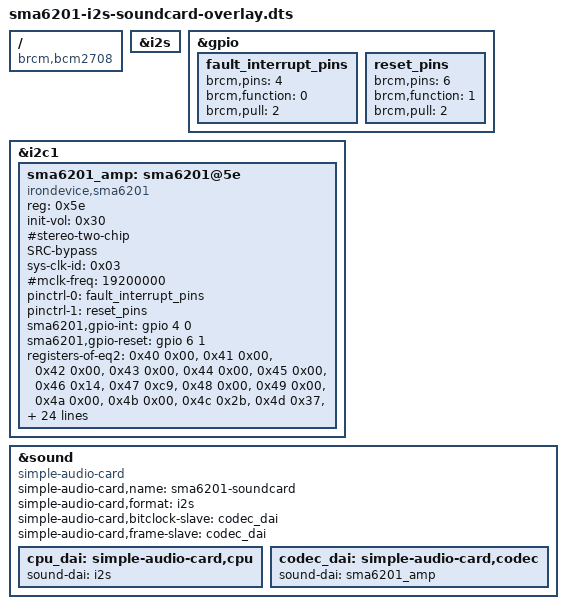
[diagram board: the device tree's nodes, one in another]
/*
 * Definitions for SMA6201 Amp
 * name : sma6201-i2s-soundcard-overlay.dts
 * Compile for dts
 * dtc -@ -I dts -O dtb -o sma6201-i2s-soundcard.dtbo
 *			sma6201-i2s-soundcard-overlay.dts
 * sudo cp sma6201-i2s-soundcard.dtbo /boot/overlays
 * adding dtoverlay sma6201-i2s-soundcard.dtbo in config.txt
 */

/dts-v1/;
/plugin/;

/ {
	compatible = "brcm,bcm2708";

	fragment@0 {
		target = <&i2s>;
		__overlay__ {
			status = "okay";
		};
	};

	fragment@1 {
		target = <&gpio>;
		__overlay__ {
			fault_interrupt_pins: fault_interrupt_pins {
				brcm,pins = <4>;
				brcm,function = <0>; /* input */
				brcm,pull = <2>; /* pull-up */
			};
			reset_pins: reset_pins {
				brcm,pins = <6>;
				brcm,function = <1>; /* Output */
				brcm,pull = <2>; /* pull-up */
			};
		};
	};

	fragment@2 {
		target = <&i2c1>;
		__overlay__ {
			#address-cells = <1>;
			#size-cells = <0>;
			status = "okay";

			sma6201_amp: sma6201@5e {
				#sound-dai-cells = <0>;
				compatible = "irondevice,sma6201";
				reg = <0x5e>;
				init-vol = <0x30>;
				#stereo-two-chip;
				SRC-bypass;
				/* SMA6201_EXTERNAL_CLOCK_19_2   : 0x00,
				 * SMA6201_EXTERNAL_CLOCK_24_576 : 0x01,
				 * SMA6201_PLL_CLKIN_MCLK        : 0x02,
				 * SMA6201_PLL_CLKIN_BCLK        : 0x03
				 */
				sys-clk-id = <0x03>;
				/* Valid when sys-clk-id 0x02 */
				#mclk-freq = <19200000>;
				pinctrl-names = "default";
				pinctrl-0 = <&fault_interrupt_pins>;
				pinctrl-1 = <&reset_pins>;
				sma6201,gpio-int= <&gpio 4 0>;
				sma6201,gpio-reset= <&gpio 6 1>;

				status = "okay";
				registers-of-eq2 = <0x40 0x00>,<0x41 0x00>,
						   <0x42 0x00>,<0x43 0x00>,
						   <0x44 0x00>,<0x45 0x00>,
						   <0x46 0x14>,<0x47 0xc9>,
						   <0x48 0x00>,<0x49 0x00>,
						   <0x4a 0x00>,<0x4b 0x00>,
						   <0x4c 0x2b>,<0x4d 0x37>,
						   <0x4e 0x00>,<0x4f 0x2a>,
						   <0x50 0x69>,<0x51 0x04>,
						   <0x52 0x99>,<0x53 0xf8>,
						   <0x54 0x02>,<0x55 0x40>,
						   <0x56 0x00>,<0x57 0x00>,
						   <0x58 0xd5>,<0x59 0x96>,
						   <0x5a 0x04>,<0x5b 0x66>,
						   <0x5c 0x07>,<0x5d 0x06>,
						   <0x5e 0x11>,<0x5f 0xb3>,
						   <0x60 0x04>,<0x61 0xce>,
						   <0x62 0x43>,<0x63 0x03>,
						   <0x64 0x40>,<0x65 0x00>,
						   <0x66 0x00>,<0x67 0xee>,
						   <0x68 0x4c>,<0x69 0x04>,
						   <0x6a 0x31>,<0x6b 0xbc>,
						   <0x6c 0x05>,<0x6d 0x0a>,
						   <0x6e 0xaa>,<0x6f 0x05>,
						   <0x70 0x00>,<0x71 0x00>,
						   <0x72 0x00>,<0x73 0x40>,
						   <0x74 0x00>,<0x75 0x00>,
						   <0x76 0xf5>,<0x77 0x55>,
						   <0x78 0x03>,<0x79 0x00>,
						   <0x7a 0x00>,<0x7b 0x00>,
						   <0x7c 0x3d>,<0x7d 0xa6>,
						   <0x7e 0x04>,<0x7f 0x82>,
						   <0x80 0x64>,<0x81 0x04>,
						   <0x82 0x40>,<0x83 0x00>,
						   <0x84 0x00>,<0x85 0xc2>,
						   <0x86 0x59>,<0x87 0x04>,
						   <0x88 0x7d>,<0x89 0x9b>,
						   <0x8a 0x04>;
				registers-of-bo = <0x05 0x18>,<0x06 0x08>,
						   <0x07 0x08>,<0x08 0x08>,
						   <0x0b 0x08>,<0x0c 0x08>,
						   <0x38 0x00>,<0x39 0x8c>,
						   <0x3a 0xcc>,<0xb0 0x85>,
						   <0xb1 0x90>,<0xb2 0x87>,
						   <0xb3 0x7f>,<0xb4 0x1f>,
						   <0xb5 0x1f>,<0xb6 0xb5>,
						   <0xb7 0x80>,<0xb8 0x77>,
						   <0xb9 0x72>,<0xba 0x6e>,
						   <0xbb 0x6a>,<0xbc 0x1f>,
						   <0xbd 0x1f>,<0xbe 0x1f>,
						   <0xbf 0x1f>,<0x1c 0x5a>,
						   <0x1d 0x40>,<0x1e 0x2e>,
						   <0x1f 0x1a>,<0x20 0x0f>;
			};
		};
	};

	fragment@3 {
		target = <&sound>;
		__overlay__ {
			compatible = "simple-audio-card";
			simple-audio-card,name = "sma6201-soundcard";
			simple-audio-card,format = "i2s";
			simple-audio-card,bitclock-slave = <&codec_dai>;
			simple-audio-card,frame-slave = <&codec_dai>;
			status = "okay";
			cpu_dai: simple-audio-card,cpu {
				sound-dai = <&i2s>;
			};
			codec_dai: simple-audio-card,codec {
				sound-dai = <&sma6201_amp>;
			};
		};
	};
};
